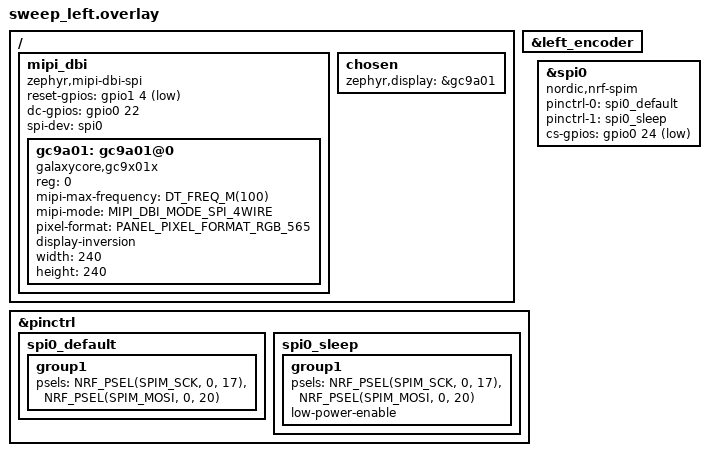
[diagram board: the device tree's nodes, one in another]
#include "sweep.dtsi"
#include <zephyr/dt-bindings/mipi_dbi/mipi_dbi.h>
#include <zephyr/dt-bindings/display/panel.h>


&left_encoder {
	status = "okay";
};

&pinctrl {
	spi0_default: spi0_default {
		group1 {
			psels = <NRF_PSEL(SPIM_SCK, 0, 17)>,
			<NRF_PSEL(SPIM_MOSI, 0, 20)>;
		};
	};
	
	spi0_sleep: spi0_sleep {
		group1 {
			psels = <NRF_PSEL(SPIM_SCK, 0, 17)>,
			<NRF_PSEL(SPIM_MOSI, 0, 20)>;
			low-power-enable;
		};
	};
};

&spi0 {
	compatible = "nordic,nrf-spim";
	status = "okay";
	pinctrl-0 = <&spi0_default>;
	pinctrl-1 = <&spi0_sleep>;
	cs-gpios = <&gpio0 24 GPIO_ACTIVE_LOW>;
	pinctrl-names = "default", "sleep";
};


/ {
	mipi_dbi {
		compatible = "zephyr,mipi-dbi-spi";
		status = "okay";
		
		reset-gpios = <&gpio1 4 GPIO_ACTIVE_LOW>;
		dc-gpios = <&gpio0 22 GPIO_ACTIVE_HIGH>;
		spi-dev = <&spi0>;
		
		#address-cells = <1>;
		#size-cells = <0>;
		
		
		gc9a01: gc9a01@0 {
			compatible = "galaxycore,gc9x01x";
			reg = <0>;
			mipi-max-frequency = <DT_FREQ_M(100)>;
			mipi-mode="MIPI_DBI_MODE_SPI_4WIRE";
			pixel-format = <PANEL_PIXEL_FORMAT_RGB_565>;
			display-inversion;
			width = <240>;
			height = <240>;
			status = "okay";
		};
		
	};
	
	chosen {
		zephyr,display = &gc9a01;
	};
};
